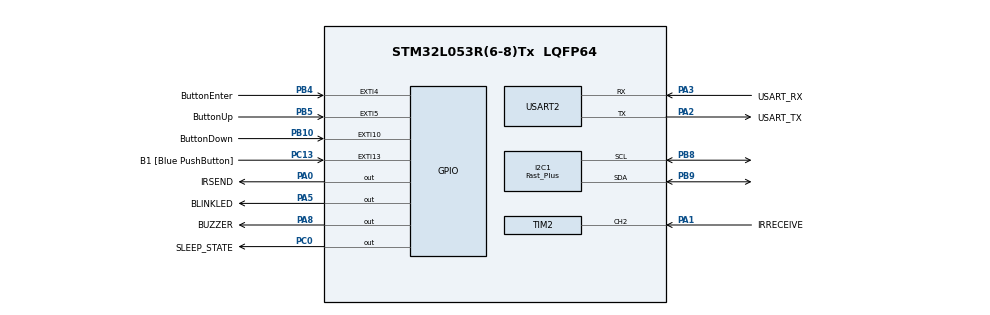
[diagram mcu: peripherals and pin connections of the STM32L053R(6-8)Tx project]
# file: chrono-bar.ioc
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FREERTOS.BinarySemaphores01=lcdSem,Dynamic,NULL
FREERTOS.Queues01=uart2TxQueue,64,uint16_t,0,Dynamic,NULL,NULL
FREERTOS.Tasks01=defaultTask,0,128,StartDefaultTask,Default,NULL,Dynamic,NULL,NULL;displayTask,-1,256,displayTaskRoutine,As external,NULL,Static,displayTaskBuffer,displayTaskControlBlock;irTask,-3,128,irTaskRoutine,As external,NULL,Static,irTaskBuffer,irTaskControlBlock
FREERTOS.configTOTAL_HEAP_SIZE=2048
FREERTOS.configUSE_TICKLESS_IDLE=1
FREERTOS.configUSE_TIMERS=1
I2C1.I2C_Speed_Mode=I2C_Fast_Plus
I2C1.Speed=1000
I2C1.Timing=0x0010030D
Mcu.Family=STM32L0
Mcu.Name=STM32L053R(6-8)Tx
Mcu.Package=LQFP64
NVIC.I2C1_IRQn=true\:3\:0\:false\:false\:false\:true\:true\:false
NVIC.TIM21_IRQn=true\:3\:0\:false\:false\:true\:true\:true\:true
NVIC.TIM2_IRQn=true\:3\:0\:false\:false\:true\:true\:true\:false
NVIC.USART2_IRQn=true\:3\:0\:false\:false\:true\:true\:true\:false
PA0.GPIO_Label=IRSEND
PA0.Signal=GPIO_Output
PA1.GPIO_Label=IRRECEIVE
PA1.Signal=S_TIM2_CH2
PA13.GPIO_Label=TMS
PA13.Mode=Serial_Wire
PA13.Signal=SYS_SWDIO
PA14.GPIO_Label=TCK
PA14.Mode=Serial_Wire
PA14.Signal=SYS_SWCLK
PA2.GPIO_Label=USART_TX
PA2.Mode=Asynchronous
PA2.Signal=USART2_TX
PA3.GPIO_Label=USART_RX
PA3.Mode=Asynchronous
PA3.Signal=USART2_RX
PA5.GPIO_Label=BLINKLED
PA5.Signal=GPIO_Output
PA8.GPIO_Label=BUZZER
PA8.Signal=GPIO_Output
PB10.GPIO_Label=ButtonDown
PB10.GPIO_ModeDefaultEXTI=GPIO_MODE_IT_FALLING
PB10.GPIO_PuPd=GPIO_NOPULL
PB10.Signal=GPXTI10
PB4.GPIO_Label=ButtonEnter
PB4.GPIO_ModeDefaultEXTI=GPIO_MODE_IT_FALLING
PB4.GPIO_PuPd=GPIO_NOPULL
PB4.Signal=GPXTI4
PB5.GPIO_Label=ButtonUp
PB5.GPIO_ModeDefaultEXTI=GPIO_MODE_IT_FALLING
PB5.GPIO_PuPd=GPIO_NOPULL
PB5.Signal=GPXTI5
PB8.Mode=I2C
PB8.Signal=I2C1_SCL
PB9.Mode=I2C
PB9.Signal=I2C1_SDA
PC0.GPIO_Label=SLEEP_STATE
PC0.Signal=GPIO_Output
PC13.GPIO_Label=B1 [Blue PushButton]
PC13.GPIO_ModeDefaultEXTI=GPIO_MODE_IT_FALLING
PC13.Signal=GPXTI13
PC14-OSC32_IN.Mode=LSE-External-Oscillator
PC14-OSC32_IN.Signal=RCC_OSC32_IN
PC15-OSC32_OUT.Mode=LSE-External-Oscillator
PC15-OSC32_OUT.Signal=RCC_OSC32_OUT
PH0-OSC_IN.Mode=HSE-External-Clock-Source
PH0-OSC_IN.Signal=RCC_OSC_IN
PH1-OSC_OUT.Signal=RCC_OSC_OUT
ProjectManager.HeapSize=0x200
ProjectManager.StackSize=0x200
ProjectManager.TargetToolchain=Makefile
RCC.AHBFreq_Value=24000000
RCC.APB1Freq_Value=24000000
RCC.APB1TimFreq_Value=24000000
RCC.APB2Freq_Value=24000000
RCC.APB2TimFreq_Value=24000000
RCC.HCLKFreq_Value=24000000
RCC.HSE_VALUE=8000000
RCC.HSI16_VALUE=16000000
RCC.HSI48_VALUE=48000000
RCC.HSI_VALUE=16000000
RCC.MSI_VALUE=2097000
RCC.SYSCLKFreq_VALUE=24000000
RCC.SYSCLKSource=RCC_SYSCLKSOURCE_PLLCLK
RCC.TimPrescaler=SYSTICK_CLKSOURCE_HCLK_DIV8
RCC.VCOOutputFreq_Value=48000000
SH.S_TIM2_CH2.0=TIM2_CH2,Input_Capture2_from_TI2
TIM2.Channel-Input_Capture1_from_TI2_63=TIM_CHANNEL_1
TIM2.Channel-Input_Capture2_from_TI2=TIM_CHANNEL_2
TIM2.ICPolarity_CH2=TIM_INPUTCHANNELPOLARITY_FALLING
TIM2.Prescaler=23
TIM2.TIM_MasterOutputTrigger=TIM_TRGO_RESET
TIM21.AutoReloadPreload=TIM_AUTORELOAD_PRELOAD_ENABLE
TIM21.ClockDivision=TIM_CLOCKDIVISION_DIV1
TIM21.Period=60000
TIM21.Prescaler=23999
TIM6.AutoReloadPreload=TIM_AUTORELOAD_PRELOAD_DISABLE
TIM6.Prescaler=23
USART2.VirtualMode-Asynchronous=VM_ASYNC
VP_FREERTOS_VS_CMSIS_V1.Mode=CMSIS_V1
VP_TIM21_VS_ClockSourceINT.Mode=Internal
VP_TIM2_VS_ClockSourceINT.Mode=Internal
VP_TIM2_VS_indirect_ch2.Mode=Input_Capture1_from_TI2_63
VP_TIM6_VS_ClockSourceINT.Mode=Enable_Timer
board=NUCLEO-L053R8

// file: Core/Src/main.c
/* USER CODE BEGIN Header */
/**
  ******************************************************************************
  * @file           : main.c
  * @brief          : Main program body
  ******************************************************************************
  * @attention
  *
  * Copyright (c) 2022 STMicroelectronics.
  * All rights reserved.
  *
  * This software is licensed under terms that can be found in the LICENSE file
  * in the root directory of this software component.
  * If no LICENSE file comes with this software, it is provided AS-IS.
  *
  ******************************************************************************
  */
/* USER CODE END Header */
#include "main.h"
#include "cmsis_os.h"
#include "i2c.h"
#include "tim.h"
#include "usart.h"
#include "gpio.h"

/* USER CODE BEGIN Includes */
#include "i2c_ll.h"
/* USER CODE END Includes */

void SystemClock_Config(void);
void MX_FREERTOS_Init(void);

int main(void)
{

  /* MCU Configuration--------------------------------------------------------*/

  /* Reset of all peripherals, Initializes the Flash interface and the Systick. */

  LL_APB2_GRP1_EnableClock(LL_APB2_GRP1_PERIPH_SYSCFG);
  LL_APB1_GRP1_EnableClock(LL_APB1_GRP1_PERIPH_PWR);

  /* System interrupt init*/
  /* PendSV_IRQn interrupt configuration */
  NVIC_SetPriority(PendSV_IRQn, 3);
  /* SysTick_IRQn interrupt configuration */
  NVIC_SetPriority(SysTick_IRQn, 3);

  /* Configure the system clock */
  SystemClock_Config();

  /* USER CODE BEGIN SysInit */
  LL_DBGMCU_EnableDBGSleepMode();
  LL_DBGMCU_EnableDBGStopMode();
  LL_DBGMCU_EnableDBGStandbyMode();
  /* USER CODE END SysInit */

  /* Initialize all configured peripherals */
  MX_GPIO_Init();
  MX_USART2_UART_Init();
  MX_I2C1_Init();
  MX_TIM2_Init();
  MX_TIM6_Init();
  MX_TIM21_Init();
  /* USER CODE BEGIN 2 */
  I2Cx_Init(I2C1);
  /* USER CODE END 2 */

  /* Call init function for freertos objects (in freertos.c) */
  MX_FREERTOS_Init();
  /* Start scheduler */
  osKernelStart();

  /* We should never get here as control is now taken by the scheduler */
  /* Infinite loop */
  while (1)
  {

  }
}

void SystemClock_Config(void)
{
  LL_FLASH_SetLatency(LL_FLASH_LATENCY_1);
  while(LL_FLASH_GetLatency()!= LL_FLASH_LATENCY_1)
  {
  }
  LL_PWR_SetRegulVoltageScaling(LL_PWR_REGU_VOLTAGE_SCALE1);
  LL_RCC_HSI_Enable();

   /* Wait till HSI is ready */
  while(LL_RCC_HSI_IsReady() != 1)
  {

  }
  LL_RCC_HSI_SetCalibTrimming(16);
  LL_RCC_PLL_ConfigDomain_SYS(LL_RCC_PLLSOURCE_HSI, LL_RCC_PLL_MUL_3, LL_RCC_PLL_DIV_2);
  LL_RCC_PLL_Enable();

   /* Wait till PLL is ready */
  while(LL_RCC_PLL_IsReady() != 1)
  {

  }
  LL_RCC_SetAHBPrescaler(LL_RCC_SYSCLK_DIV_1);
  LL_RCC_SetAPB1Prescaler(LL_RCC_APB1_DIV_1);
  LL_RCC_SetAPB2Prescaler(LL_RCC_APB2_DIV_1);
  LL_RCC_SetSysClkSource(LL_RCC_SYS_CLKSOURCE_PLL);

   /* Wait till System clock is ready */
  while(LL_RCC_GetSysClkSource() != LL_RCC_SYS_CLKSOURCE_STATUS_PLL)
  {

  }

  LL_Init1msTick(3000000);

  LL_SetSystemCoreClock(24000000);
  LL_RCC_SetUSARTClockSource(LL_RCC_USART2_CLKSOURCE_PCLK1);
  LL_RCC_SetI2CClockSource(LL_RCC_I2C1_CLKSOURCE_PCLK1);
}

void Error_Handler(void)
{
  __disable_irq();
  while (1)
  {
  }
}

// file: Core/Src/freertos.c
/* USER CODE BEGIN Header */
/**
  ******************************************************************************
  * File Name          : freertos.c
  * Description        : Code for freertos applications
  ******************************************************************************
  * @attention
  *
  * Copyright (c) 2022 STMicroelectronics.
  * All rights reserved.
  *
  * This software is licensed under terms that can be found in the LICENSE file
  * in the root directory of this software component.
  * If no LICENSE file comes with this software, it is provided AS-IS.
  *
  ******************************************************************************
  */
/* USER CODE END Header */

#include "FreeRTOS.h"
#include "task.h"
#include "main.h"
#include "cmsis_os.h"

osThreadId defaultTaskHandle;
osThreadId displayTaskHandle;
uint32_t displayTaskBuffer[ 256 ];
osStaticThreadDef_t displayTaskControlBlock;
osThreadId irTaskHandle;
uint32_t irTaskBuffer[ 128 ];
osStaticThreadDef_t irTaskControlBlock;
osMessageQId uart2TxQueueHandle;
osSemaphoreId lcdSemHandle;

void StartDefaultTask(void const * argument);
extern void displayTaskRoutine(void const * argument);
extern void irTaskRoutine(void const * argument);

void MX_FREERTOS_Init(void); /* (MISRA C 2004 rule 8.1) */

/* GetIdleTaskMemory prototype (linked to static allocation support) */
void vApplicationGetIdleTaskMemory( StaticTask_t **ppxIdleTaskTCBBuffer, StackType_t **ppxIdleTaskStackBuffer, uint32_t *pulIdleTaskStackSize );

/* GetTimerTaskMemory prototype (linked to static allocation support) */
void vApplicationGetTimerTaskMemory( StaticTask_t **ppxTimerTaskTCBBuffer, StackType_t **ppxTimerTaskStackBuffer, uint32_t *pulTimerTaskStackSize );

/* USER CODE BEGIN PREPOSTSLEEP */
__WEAK void PreSleepProcessing(uint32_t *ulExpectedIdleTime)
{
/* place for user code */
  LL_GPIO_ResetOutputPin(SLEEP_STATE_GPIO_Port, SLEEP_STATE_Pin);
}

__WEAK void PostSleepProcessing(uint32_t *ulExpectedIdleTime)
{
/* place for user code */
  LL_GPIO_SetOutputPin(SLEEP_STATE_GPIO_Port, SLEEP_STATE_Pin);
}
/* USER CODE END PREPOSTSLEEP */

/* USER CODE BEGIN GET_IDLE_TASK_MEMORY */
static StaticTask_t xIdleTaskTCBBuffer;
static StackType_t xIdleStack[configMINIMAL_STACK_SIZE];

void vApplicationGetIdleTaskMemory( StaticTask_t **ppxIdleTaskTCBBuffer, StackType_t **ppxIdleTaskStackBuffer, uint32_t *pulIdleTaskStackSize )
{
  *ppxIdleTaskTCBBuffer = &xIdleTaskTCBBuffer;
  *ppxIdleTaskStackBuffer = &xIdleStack[0];
  *pulIdleTaskStackSize = configMINIMAL_STACK_SIZE;
  /* place for user code */
}
/* USER CODE END GET_IDLE_TASK_MEMORY */

/* USER CODE BEGIN GET_TIMER_TASK_MEMORY */
static StaticTask_t xTimerTaskTCBBuffer;
static StackType_t xTimerStack[configTIMER_TASK_STACK_DEPTH];

void vApplicationGetTimerTaskMemory( StaticTask_t **ppxTimerTaskTCBBuffer, StackType_t **ppxTimerTaskStackBuffer, uint32_t *pulTimerTaskStackSize )
{
  *ppxTimerTaskTCBBuffer = &xTimerTaskTCBBuffer;
  *ppxTimerTaskStackBuffer = &xTimerStack[0];
  *pulTimerTaskStackSize = configTIMER_TASK_STACK_DEPTH;
  /* place for user code */
}
/* USER CODE END GET_TIMER_TASK_MEMORY */

void MX_FREERTOS_Init(void) {

  /* Create the semaphores(s) */
  /* definition and creation of lcdSem */
  osSemaphoreDef(lcdSem);
  lcdSemHandle = osSemaphoreCreate(osSemaphore(lcdSem), 1);

  /* Create the queue(s) */
  /* definition and creation of uart2TxQueue */
  osMessageQDef(uart2TxQueue, 64, uint16_t);
  uart2TxQueueHandle = osMessageCreate(osMessageQ(uart2TxQueue), NULL);

  /* Create the thread(s) */
  /* definition and creation of defaultTask */
  osThreadDef(defaultTask, StartDefaultTask, osPriorityNormal, 0, 128);
  defaultTaskHandle = osThreadCreate(osThread(defaultTask), NULL);

  /* definition and creation of displayTask */
  osThreadStaticDef(displayTask, displayTaskRoutine, osPriorityBelowNormal, 0, 256, displayTaskBuffer, &displayTaskControlBlock);
  displayTaskHandle = osThreadCreate(osThread(displayTask), NULL);

  /* definition and creation of irTask */
  osThreadStaticDef(irTask, irTaskRoutine, osPriorityIdle, 0, 128, irTaskBuffer, &irTaskControlBlock);
  irTaskHandle = osThreadCreate(osThread(irTask), NULL);

}

void StartDefaultTask(void const * argument)
{
  /* USER CODE BEGIN StartDefaultTask */

  /* It`s unable in STM32CubeMX to configure SysTick`s frequency other
     than SystemCoreClock. So it`s should be reconfigured manualy
     after OS scheduler is started (see prvSetupTimerInterrupt( void )). */
  SysTick->CTRL  = 0UL;
  SysTick->VAL   = 0UL;
  SysTick->LOAD  = ( configSYSTICK_CLOCK_HZ / configTICK_RATE_HZ ) - 1UL;
  SysTick->CTRL  = (configSYSTICK_CLOCK_HZ == configCPU_CLOCK_HZ ? SysTick_CTRL_CLKSOURCE_Msk : 0) |
                    SysTick_CTRL_TICKINT_Msk | SysTick_CTRL_ENABLE_Msk;

  osThreadTerminate(NULL);
  /* Infinite loop */
  for(;;)
  {
    osDelay(1);
  }
  /* USER CODE END StartDefaultTask */
}
